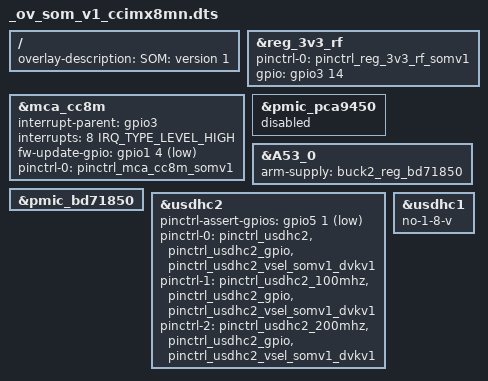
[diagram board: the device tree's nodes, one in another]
/*
 * Copyright 2019, 2020 Digi International Inc.
 *
 * Permission to use, copy, modify, and/or distribute this software for any
 * purpose with or without fee is hereby granted, provided that the above
 * copyright notice and this permission notice appear in all copies.
 * THE SOFTWARE IS PROVIDED "AS IS" AND THE AUTHOR DISCLAIMS ALL WARRANTIES
 * WITH REGARD TO THIS SOFTWARE INCLUDING ALL IMPLIED WARRANTIES OF
 * MERCHANTABILITY AND FITNESS. IN NO EVENT SHALL THE AUTHOR BE LIABLE FOR
 * ANY SPECIAL, DIRECT, INDIRECT, OR CONSEQUENTIAL DAMAGES OR ANY DAMAGES
 * WHATSOEVER RESULTING FROM LOSS OF USE, DATA OR PROFITS, WHETHER IN AN
 * ACTION OF CONTRACT, NEGLIGENCE OR OTHER TORTIOUS ACTION, ARISING OUT OF
 * OR IN CONNECTION WITH THE USE OR PERFORMANCE OF THIS SOFTWARE.
 */

#include <dt-bindings/gpio/gpio.h>
#include <dt-bindings/interrupt-controller/arm-gic.h>

/dts-v1/;
/plugin/;

/*
 * Overlay to support SOMv1 on ccimx8mn device trees.
 *
 * The main changes for SOMv1 are:
 * - Disable PCA9450 PMIC and enable BD71850 PMIC instead.
 * - Select BD71850 PMIC regulators where required.
 * - 3V3_RF_EN signal is controlled by NAND_DQS pad (GPIO3_IO14).
 * - MCA_FW_UPDATE signal is controlled by GPIO1_IO04 pad.
 * - MCA_nINT signal is managed by NAND_DATA02 pad (GPIO3_IO8).
 * - Wireless interface SDHC1 is supplied at 3V3 instead of 1V8.
 */
/ {
	fragment@0 {
		target-path = "/";
		__overlay__ {
			overlay-description = "SOM: version 1";
		};
	};

	/* Update 3V3_RF regulator GPIO */
	fragment@1 {
		target = <&reg_3v3_rf>;
		__overlay__ {
			pinctrl-0 = <&pinctrl_reg_3v3_rf_somv1>;
			gpio = <&gpio3 14 GPIO_ACTIVE_HIGH>; /* 3V3_RF_EN */
		};
	};

	/* Update MCA GPIOs */
	fragment@2 {
		target = <&mca_cc8m>;
		__overlay__ {
			interrupt-parent = <&gpio3>;
			interrupts = <8 IRQ_TYPE_LEVEL_HIGH>;
			fw-update-gpio = <&gpio1 4 GPIO_ACTIVE_LOW>;
			pinctrl-0 = <&pinctrl_mca_cc8m_somv1>;
		};
	};

	/* Disable NXP PCA9450 PMIC */
	fragment@3 {
		target = <&pmic_pca9450>;
		__overlay__ {
			/* This PMIC was introduced in SOMv2 */
			status = "disabled";
		};
	};

	/* Enable ROHM BD71850 PMIC */
	fragment@4 {
		target = <&A53_0>;
		__overlay__ {
			arm-supply = <&buck2_reg_bd71850>;
		};
	};

	fragment@5 {
		target = <&pmic_bd71850>;
		__overlay__ {
			status = "okay";
		};
	};

	/* Update uSD MUX_VSELECT pin for somv1 on dvkv1 */
	fragment@6 {
		target = <&usdhc2>;
		__overlay__ {
			/* Assert GPIO5_IO1 low for 3V3 (def) or high for 1.8V */
			pinctrl-assert-gpios = <&gpio5 1 GPIO_ACTIVE_LOW>;
			pinctrl-0 = <&pinctrl_usdhc2>,
				    <&pinctrl_usdhc2_gpio>,
				    <&pinctrl_usdhc2_vsel_somv1_dvkv1>;
			pinctrl-1 = <&pinctrl_usdhc2_100mhz>,
				    <&pinctrl_usdhc2_gpio>,
				    <&pinctrl_usdhc2_vsel_somv1_dvkv1>;
			pinctrl-2 = <&pinctrl_usdhc2_200mhz>,
				    <&pinctrl_usdhc2_gpio>,
				    <&pinctrl_usdhc2_vsel_somv1_dvkv1>;
		};
	};

	/* Wireless interface is supplied to 3V3 in somv1 */
	fragment@7 {
		target = <&usdhc1>;
		__overlay__ {
			no-1-8-v;
		};
	};
};
